# APM32F411 register map
Vendor: Geehy; File version: 2024.11.05
CPU: CM4 r1p0, little endian, 3 interrupt priority bits
Registers are 32-bit, read-write, reset 0x0 unless marked. A register's access mark holds for its fields unless they carry their own. Offsets are from the block's base; [hi:lo] are bit positions; {n}, {i} and the like mark numbered series; 'fields as' and 'values as' point back to an identical list.

## OTG_FS_DEVICE — USB on the go full speed
Base 0x50000800
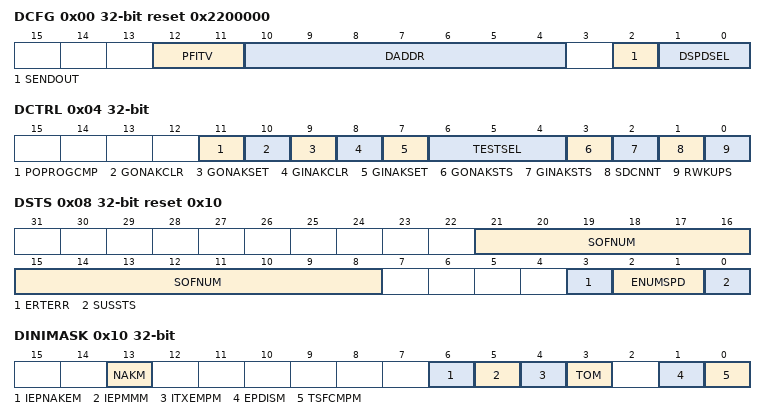
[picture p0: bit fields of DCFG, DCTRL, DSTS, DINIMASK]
0x00 DCFG reset 0x2200000 — OTG_FS device configuration register (OTG_FS_DCFG)
  [12:11] PFITV — Periodic frame interval
  [10:4] DADDR — Device address
  [2] SENDOUT — Non-zero-length status OUT handshake
  [1:0] DSPDSEL — Device speed
0x04 DCTRL access per field — OTG_FS device control register (OTG_FS_DCTL)
  [11] POPROGCMP rw — Power-on programming done
  [10] GONAKCLR rw — Clear global OUT NAK
  [9] GONAKSET rw — Set global OUT NAK
  [8] GINAKCLR rw — Clear global IN NAK
  [7] GINAKSET rw — Set global IN NAK
  [6:4] TESTSEL rw — Test control
  [3] GONAKSTS ro — Global OUT NAK status
  [2] GINAKSTS ro — Global IN NAK status
  [1] SDCNNT rw — Soft disconnect
  [0] RWKUPS rw — Remote wakeup signaling
0x08 DSTS ro reset 0x10 — OTG_FS device status register (OTG_FS_DSTS)
  [21:8] SOFNUM — Frame number of the received SOF
  [3] ERTERR — Erratic error
  [2:1] ENUMSPD — Enumerated speed
  [0] SUSSTS — Suspend status
0x10 DINIMASK — OTG_FS device IN endpoint common interrupt mask register (OTG_FS_DIEPMSK)
  [13] NAKM — NAK Interrupt Mask
  [6] IEPNAKEM — IN endpoint NAK effective mask
  [5] IEPMMM — IN token received with EP mismatch mask
  [4] ITXEMPM — IN token received when TxFIFO empty mask
  [3] TOM — Timeout condition mask (Non-isochronous endpoints)
  [1] EPDISM — Endpoint disabled interrupt mask
  [0] TSFCMPM — Transfer completed interrupt mask
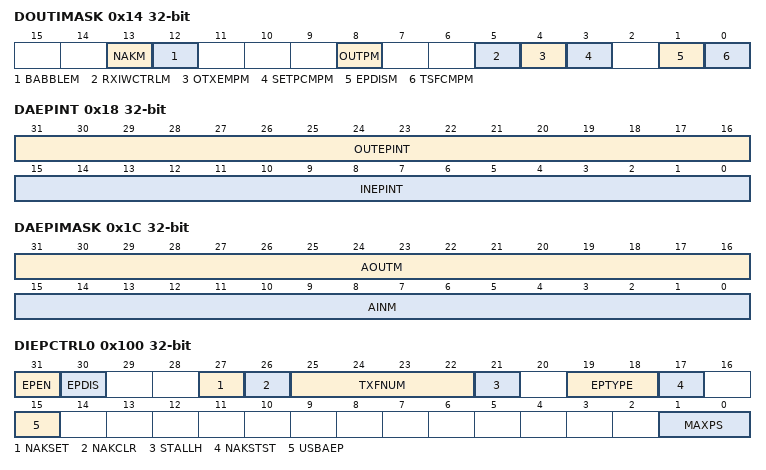
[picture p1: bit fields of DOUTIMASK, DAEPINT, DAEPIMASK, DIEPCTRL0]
0x14 DOUTIMASK — OTG_FS device OUT endpoint common interrupt mask register (OTG_FS_DOEPMSK)
  [13] NAKM — NAK Interrupt Mask
  [12] BABBLEM — Babble Error Interrupt Mask
  [8] OUTPM — OUT Packet Error Interrupt Mask
  [5] RXIWCTRLM — Receive Interrupt when Control Mask
  [4] OTXEMPM — OUT token received when endpoint disabled mask
  [3] SETPCMPM — SETUP phase done mask
  [1] EPDISM — Endpoint disabled interrupt mask
  [0] TSFCMPM — Transfer completed interrupt mask
0x18 DAEPINT ro — OTG_FS device all endpoints interrupt register (OTG_FS_DAINT)
  [31:16] OUTEPINT — OUT endpoint interrupt bits
  [15:0] INEPINT — IN endpoint interrupt bits
0x1C DAEPIMASK — OTG_FS all endpoints interrupt mask register (OTG_FS_DAINTMSK)
  [31:16] AOUTM — OUT endpoint interrupt bits
  [15:0] AINM — IN EP interrupt mask bits
0x28 DVBUSDTIM reset 0x17D7 — OTG_FS device VBUS discharge time register
  [15:0] VBUSDTIM — Device VBUS discharge time
0x2C DVBUSPTIM reset 0x5B8 — OTG_FS device VBUS pulsing time register
  [11:0] VBUSPTIM — Device VBUS pulsing time
0x34 DIEIMASK — OTG_FS device IN endpoint FIFO empty interrupt mask register
  [15:0] INEM — IN EP Tx FIFO empty interrupt mask bits
0x100 DIEPCTRL0 access per field — OTG_FS device control IN endpoint 0 control register (OTG_FS_DIEPCTL0)
  [31] EPEN ro — Endpoint enable
  [30] EPDIS ro — Endpoint disable
  [27] NAKSET wo — Set NAK
  [26] NAKCLR wo — Clear NAK
  [25:22] TXFNUM rw — TxFIFO number
  [21] STALLH rw — STALL handshake
  [19:18] EPTYPE ro — Endpoint type
  [17] NAKSTST ro — NAK status
  [15] USBAEP ro — USB active endpoint
  [1:0] MAXPS rw — Maximum packet size
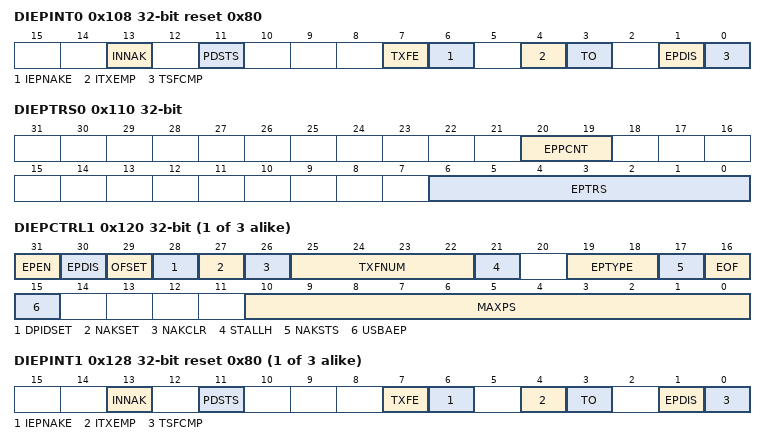
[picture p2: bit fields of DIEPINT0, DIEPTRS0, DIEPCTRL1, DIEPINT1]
0x108 DIEPINT0 access per field reset 0x80 — device endpoint-x interrupt register
  [13] INNAK rw — Input NAK Interrupt
  [11] PDSTS rw — Packet Dropped Status
  [7] TXFE ro — TXFIFO Empty Interrupt
  [6] IEPNAKE rw — IN Endpoint NAK Effective
  [4] ITXEMP rw — Receive IN Token Interrupt
  [3] TO rw — Timeout Interrupt
  [1] EPDIS rw — Endpoint Interrupt Disable
  [0] TSFCMP rw — Transfer Complete Interrupt
0x110 DIEPTRS0 — device endpoint-0 transfer size register
  [20:19] EPPCNT — Packet count
  [6:0] EPTRS — Transfer size
{0x118+0x20*i} DITXFSTS{i} ro (i=0..3) — OTG_FS device IN endpoint transmit FIFO status register
  [15:0] INEPTXFSASEL — IN endpoint TxFIFO space available
{0x100+0x20*i} DIEPCTRL{i} access per field (i=1..3) — OTG device endpoint-{i} control register
  [31] EPEN rw — Endpoint Enable
  [30] EPDIS rw — Endpoint Disable
  [29] OFSET wo — Odd Frame Set
  [28] DPIDSET wo — DATA0 PID Set
  [27] NAKSET wo
  [26] NAKCLR wo — NAK Clear
  [25:22] TXFNUM rw — TXFIFO Number
  [21] STALLH rw — STALL Handshake
  [19:18] EPTYPE rw — Endpoint Type
  [17] NAKSTS ro — NAK Status Configure
  [16] EOF ro — Even Odd Frame Select
  [15] USBAEP rw — USB Active Endpoint
  [10:0] MAXPS rw — Maximum Packet Size
{0x108+0x20*i} DIEPINT{i} access per field reset 0x80 (i=1..3) — device endpoint-{i} interrupt register
  fields as DIEPINT0
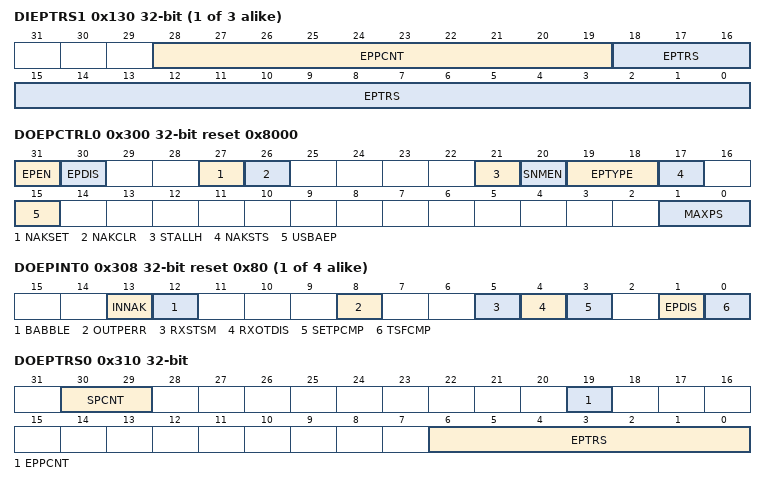
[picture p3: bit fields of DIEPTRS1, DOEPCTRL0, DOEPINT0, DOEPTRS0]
{0x110+0x20*i} DIEPTRS{i} (i=1..3) — device endpoint-{i} transfer size register
  [28:19] EPPCNT — Packet count
  [18:0] EPTRS — Transfer size
0x300 DOEPCTRL0 access per field reset 0x8000 — device endpoint-0 control register
  [31] EPEN wo — Endpoint Enable
  [30] EPDIS ro — Endpoint Disable
  [27] NAKSET wo
  [26] NAKCLR wo — NAK Clear
  [21] STALLH rw — STALL Handshake
  [20] SNMEN rw — Snoop Mode Enable
  [19:18] EPTYPE ro — Endpoint Type
  [17] NAKSTS ro — NAK Status Configure
  [15] USBAEP ro — USB Active Endpoint
  [1:0] MAXPS ro — Maximum Packet Size
{0x308+0x20*i} DOEPINT{i} reset 0x80 (i=0..3) — device endpoint-{i} interrupt register
  [13] INNAK — Input NAK Interrupt
  [12] BABBLE — Babble Error Interrupt
  [8] OUTPERR — OUT Packet Error Interrupt Mask
  [5] RXSTSM — Receive Interrupt Status when Write Control Mask
  [4] RXOTDIS — Receive OUT Token Disable Interrupt
  [3] SETPCMP — SETUP Phase Complete Interrupt
  [1] EPDIS — Endpoint Interrupt Disable
  [0] TSFCMP — Transfer Complete Interrupt
0x310 DOEPTRS0 — device OUT endpoint-0 transfer size register
  [30:29] SPCNT — SETUP packet count
  [19] EPPCNT — Packet count
  [6:0] EPTRS — Transfer size
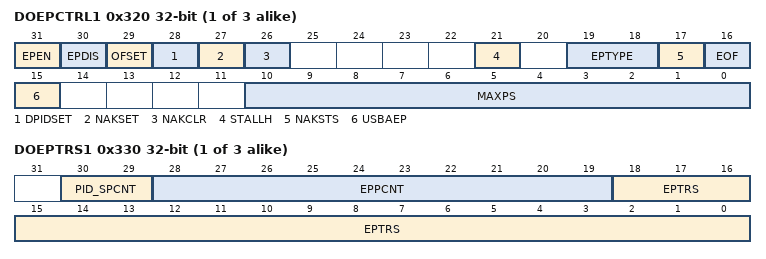
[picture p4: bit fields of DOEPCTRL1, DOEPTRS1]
{0x300+0x20*i} DOEPCTRL{i} access per field (i=1..3) — device endpoint-{i} control register
  [31] EPEN rw — Endpoint Enable
  [30] EPDIS rw — Endpoint Disable
  [29] OFSET wo — Odd Frame Set
  [28] DPIDSET wo — DATA0 PID Set
  [27] NAKSET wo
  [26] NAKCLR wo — NAK Clear
  [21] STALLH rw — STALL Handshake
  [19:18] EPTYPE rw — Endpoint Type
  [17] NAKSTS ro — NAK Status Configure
  [16] EOF ro — Even Odd Frame Select
  [15] USBAEP rw — USB Active Endpoint
  [10:0] MAXPS rw — Maximum Packet Size
{0x310+0x20*i} DOEPTRS{i} (i=1..3) — device OUT endpoint-{i} transfer size register
  [30:29] PID_SPCNT — Received data PID/SETUP packet count
  [28:19] EPPCNT — Packet count
  [18:0] EPTRS — Transfer size
